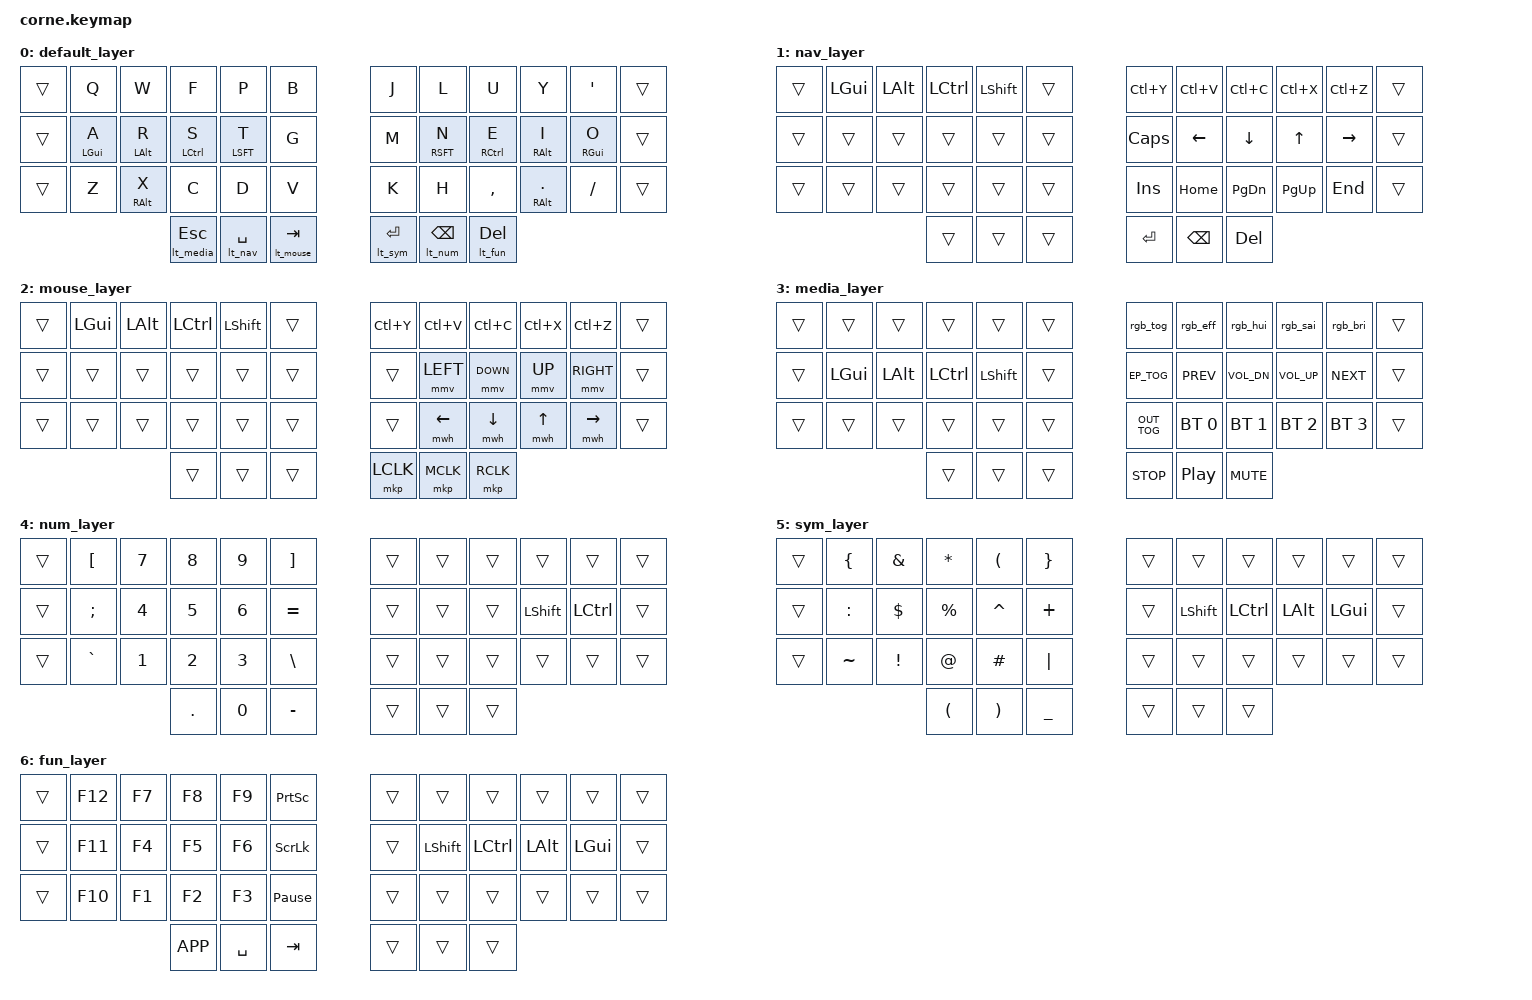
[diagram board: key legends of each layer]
#include <behaviors.dtsi>
#include <dt-bindings/zmk/keys.h>
#include <dt-bindings/zmk/bt.h>
#include <dt-bindings/zmk/rgb.h>
#include <dt-bindings/zmk/outputs.h>
#include <dt-bindings/zmk/ext_power.h>
#include <dt-bindings/zmk/mouse.h>

/ {
    behaviors {
        // Miryoku Behaviors
        hrm: hrm {
            compatible = "zmk,behavior-hold-tap";
            label = "MIRYOKU_HOLD_TAP";
            #binding-cells = <2>;
            tapping-term-ms = <200>;
            quick-tap-ms = <200>;
            flavor = "tap-preferred";
            bindings = <&kp>, <&kp>;
        };

        lt_nav: lt_nav { compatible = "zmk,behavior-layer-tap"; label = "LT_NAV"; #binding-cells = <2>; tapping-term-ms = <200>; bindings = <&mo 4>, <&kp>; };
        lt_mouse: lt_mouse { compatible = "zmk,behavior-layer-tap"; label = "LT_MOUSE"; #binding-cells = <2>; tapping-term-ms = <200>; bindings = <&mo 5>, <&kp>; };
        lt_media: lt_media { compatible = "zmk,behavior-layer-tap"; label = "LT_MEDIA"; #binding-cells = <2>; tapping-term-ms = <200>; bindings = <&mo 6>, <&kp>; };
        lt_num: lt_num { compatible = "zmk,behavior-layer-tap"; label = "LT_NUM"; #binding-cells = <2>; tapping-term-ms = <200>; bindings = <&mo 7>, <&kp>; };
        lt_sym: lt_sym { compatible = "zmk,behavior-layer-tap"; label = "LT_SYM"; #binding-cells = <2>; tapping-term-ms = <200>; bindings = <&mo 8>, <&kp>; };
        lt_fun: lt_fun { compatible = "zmk,behavior-layer-tap"; label = "LT_FUN"; #binding-cells = <2>; tapping-term-ms = <200>; bindings = <&mo 9>, <&kp>; };
    };

    keymap {
        compatible = "zmk,keymap";

        default_layer {
            // ------------------------------------------------------------------------------------------------------------------
            // |  NONE  | | Q      | W      | F      | P      | B      | | J      | L      | U      | Y      | '      | |  NONE  |
            // |  NONE  | | A(GUI) | R(ALT) | S(CTL) | T(SFT) | G      | | M      | N(SFT) | E(CTL) | I(ALT) | O(GUI) | |  NONE  |
            // |  NONE  | | Z(BTN) | X(ALT) | C      | D      | V      | | K      | H      | ,      | .(ALT) | /(BTN) | |  NONE  |
            //                        | ESC(MED) | SPC(NAV) | TAB(MSE) | | ENT(SYM) | BSP(NUM) | DEL(FUN) |
            bindings = <
                &trans &kp Q      &kp W      &kp F      &kp P      &kp B                     &kp J      &kp L      &kp U      &kp Y      &kp SQT    &trans
                &trans &hrm LGUI A &hrm LALT R &hrm LCTL S &hrm LSFT T &kp G                    &kp M      &hrm RSFT N &hrm RCTL E &hrm RALT I &hrm RGUI O &trans
                &trans &kp Z &hrm RALT X &kp C      &kp D      &kp V                     &kp K      &kp H      &kp COMMA  &hrm RALT DOT &kp SLASH &trans
                               &lt_media ESC &lt_nav SPACE &lt_mouse TAB      &lt_sym RET &lt_num BSPC &lt_fun DEL
            >;
        };
        
        nav_layer {
            // ------------------------------------------------------------------------------------------------------------------
            // |  NONE  | | GUI    | ALT    | CTL    | SFT    | NONE   | | REDO   | PASTE  | COPY   | CUT    | UNDO   | |  NONE  |
            // |  NONE  | | NONE   | NONE   | NONE   | NONE   | NONE   | | CAPS   | LEFT   | DOWN   | UP     | RIGHT  | |  NONE  |
            // |  NONE  | | NONE   | NONE   | NONE   | NONE   | NONE   | | INS    | HOME   | PGDN   | PGUP   | END    | |  NONE  |
            //                        | NONE   | NONE   | NONE   | | ENT    | BSP    | DEL    |
            bindings = <
                &trans &kp LGUI   &kp LALT   &kp LCTRL  &kp LSHFT  &trans                  &kp LC(Y) &kp LC(V) &kp LC(C) &kp LC(X) &kp LC(Z) &trans
                &trans &trans   &trans   &trans   &trans   &trans                  &kp CAPS   &kp LEFT  &kp DOWN  &kp UP    &kp RIGHT &trans
                &trans &trans   &trans   &trans   &trans   &trans                  &kp INS    &kp HOME  &kp PG_DN &kp PG_UP &kp END     &trans
                               &trans &trans &trans          &kp RET   &kp BSPC  &kp DEL
            >;
        };

        mouse_layer {
            // ------------------------------------------------------------------------------------------------------------------
            // |  NONE  | | GUI    | ALT    | CTL    | SFT    | NONE   | | REDO   | PASTE  | COPY   | CUT    | UNDO   | |  NONE  |
            // |  NONE  | | NONE   | NONE   | NONE   | NONE   | NONE   | | NONE   | MsLeft | MsDown | MsUp   | MsRight| |  NONE  |
            // |  NONE  | | NONE   | NONE   | NONE   | NONE   | NONE   | | NONE   | WhLeft | WhDown | WhUp   | WhRight| |  NONE  |
            //                        | NONE   | NONE   | NONE   | | LClick | MClick | RClick |
            bindings = <
                &trans &kp LGUI   &kp LALT   &kp LCTRL  &kp LSHFT  &trans                  &kp LC(Y) &kp LC(V) &kp LC(C) &kp LC(X) &kp LC(Z) &trans
                &trans &trans   &trans   &trans   &trans   &trans                  &trans   &mmv LEFT &mmv DOWN &mmv UP   &mmv RIGHT &trans
                &trans &trans   &trans   &trans   &trans   &trans                  &trans   &mwh LEFT &mwh DOWN &mwh UP   &mwh RIGHT &trans
                               &trans &trans &trans          &mkp LCLK &mkp MCLK &mkp RCLK
            >;
        };

        media_layer {
            // ------------------------------------------------------------------------------------------------------------------
            // |  NONE  | | NONE   | NONE   | NONE   | NONE   | NONE   | | RGBTog | RGBMod | RGBHue | RGBSat | RGBVal | |  NONE  |
            // |  NONE  | | GUI    | ALT    | CTL    | SFT    | NONE   | | EPTog  | Prev   | VolDn  | VolUp  | Next   | |  NONE  |
            // |  NONE  | | NONE   | NONE   | NONE   | NONE   | NONE   | | OutTog | BT_0   | BT_1   | BT_2   | BT_3   | |  NONE  |
            //                        | NONE   | NONE   | NONE   | | Stop   | Play   | Mute   |
            bindings = <
                &trans &trans   &trans   &trans   &trans   &trans      &rgb_tog &rgb_eff &rgb_hui &rgb_sai &rgb_bri &trans
                &trans &kp LGUI  &kp LALT  &kp LCTRL &kp LSHFT &trans      &kp EP_TOG &kp C_PREV &kp C_VOL_DN &kp C_VOL_UP &kp C_NEXT &trans
                &trans &trans   &trans   &trans   &trans   &trans      &kp OUT_TOG &bt BT_SEL 0 &bt BT_SEL 1 &bt BT_SEL 2 &bt BT_SEL 3 &trans
                               &trans &trans &trans          &kp C_STOP &kp C_PP     &kp C_MUTE
            >;
        };

        num_layer {
            // ------------------------------------------------------------------------------------------------------------------
            // |  NONE  | | [      | 7      | 8      | 9      | ]      | | NONE   | NONE   | NONE   | NONE   | NONE   | |  NONE  |
            // |  NONE  | | ;      | 4      | 5      | 6      | =      | | NONE   | SFT    | CTL    | ALT    | GUI    | |  NONE  |
            // |  NONE  | | `      | 1      | 2      | 3      | \      | | NONE   | NONE   | NONE   | NONE   | NONE   | |  NONE  |
            //                        | .      | 0      | -      | | NONE   | NONE   | NONE   |
            bindings = <
                &trans &kp LBKT &kp N7 &kp N8 &kp N9 &kp RBKT          &trans &trans &trans &trans &trans &trans
                &trans &kp SEMI &kp N4 &kp N5 &kp N6 &kp EQUAL         &trans &trans &trans &kp LSHFT &kp LCTRL &trans
                &trans &kp GRAVE &kp N1 &kp N2 &kp N3 &kp BSLH          &trans &trans &trans &trans &trans &trans
                               &kp DOT &kp N0 &kp MINUS          &trans &trans &trans
            >;
        };

        sym_layer {
            // ------------------------------------------------------------------------------------------------------------------
            // |  NONE  | | {      | &      | *      | (      | }      | | NONE   | NONE   | NONE   | NONE   | NONE   | |  NONE  |
            // |  NONE  | | :      | $      | %      | ^      | +      | | NONE   | SFT    | CTL    | ALT    | GUI    | |  NONE  |
            // |  NONE  | | ~      | !      | @      | #      | |      | | NONE   | NONE   | NONE   | NONE   | NONE   | |  NONE  |
            //                        | (      | )      | _      | | NONE   | NONE   | NONE   |
            bindings = <
                &trans &kp LBRC &kp AMPS &kp ASTRK &kp LPAR &kp RBRC          &trans &trans &trans &trans &trans &trans
                &trans &kp COLON &kp DLLR &kp PRCNT &kp CARET &kp PLUS          &trans &kp LSHFT &kp LCTRL &kp LALT &kp LGUI &trans
                &trans &kp TILDE &kp EXCL &kp AT   &kp HASH &kp PIPE          &trans &trans &trans &trans &trans &trans
                               &kp LPAR &kp RPAR &kp UNDER          &trans &trans &trans
            >;
        };

        fun_layer {
            // ------------------------------------------------------------------------------------------------------------------
            // |  NONE  | | F12    | F7     | F8     | F9     | PrtSc  | | NONE   | NONE   | NONE   | NONE   | NONE   | |  NONE  |
            // |  NONE  | | F11    | F4     | F5     | F6     | ScrLk  | | NONE   | SFT    | CTL    | ALT    | GUI    | |  NONE  |
            // |  NONE  | | F10    | F1     | F2     | F3     | Pause  | | NONE   | NONE   | NONE   | NONE   | NONE   | |  NONE  |
            //                        | APP    | SPC    | TAB    | | NONE   | NONE   | NONE   |
            bindings = <
                &trans &kp F12 &kp F7 &kp F8 &kp F9 &kp PSCRN         &trans &trans &trans &trans &trans &trans
                &trans &kp F11 &kp F4 &kp F5 &kp F6 &kp SLCK          &trans &kp LSHFT &kp LCTRL &kp LALT &kp LGUI &trans
                &trans &kp F10 &kp F1 &kp F2 &kp F3 &kp PAUSE_BREAK   &trans &trans &trans &trans &trans &trans
                               &kp K_APP &kp SPACE &kp TAB          &trans &trans &trans
            >;
        };
    };
};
